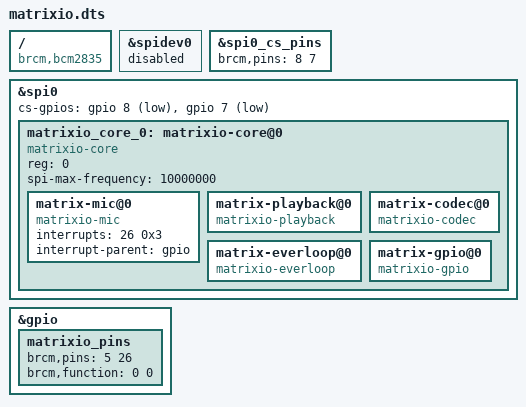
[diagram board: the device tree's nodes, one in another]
/dts-v1/;
/plugin/;

/ {
	compatible = "brcm,bcm2835";

	fragment@0 {
		target = <&spidev0>;
		__overlay__ { status = "disabled"; };
	};

	fragment@1 {
		target = <&spi0_cs_pins>;
		frag1: __overlay__ {
			brcm,pins = <8 7>;
		};
	};

	fragment@2 {
		target = <&spi0>;
		frag2: __overlay__ {
			cs-gpios = <&gpio 8 1>, <&gpio 7 1>;
			status = "okay";

			#address-cells = <1>;
			#size-cells = <0>;

			matrixio_core_0: matrixio-core@0{
				compatible = "matrixio-core";
				reg = <0>;
				spi-max-frequency = <10000000>;
				status = "okay";
			};
		};
	};

	fragment@3 {
		target = <&gpio>;
		__overlay__ {
			matrixio_pins: matrixio_pins {
				brcm,pins = <5 26>; /* pin 26 for general GPIO, pin 5 for reset */
				brcm,function = <0 0>;
			};
		};
	};

        fragment@10 {
                target = <&matrixio_core_0>;
                __overlay__ {
                        matrix-mic@0 {
                                compatible = "matrixio-mic";
                                interrupts = <26 0x3>; /* CHANGED: Use pin 26 instead of pin 6 */
                                interrupt-parent = <&gpio>;
                        };
                };
        };
        fragment@11 {
                target = <&matrixio_core_0>;
                __overlay__ {
                        matrix-playback@0 {
                                compatible = "matrixio-playback";
                        };
                };
        };
        fragment@12 {
                target = <&matrixio_core_0>;
                __overlay__ {
                        matrix-codec@0 {
                                compatible = "matrixio-codec";
                        };
                };
        };
        fragment@13 {
                target = <&matrixio_core_0>;
                __overlay__ {
                        matrix-everloop@0 {
                                compatible = "matrixio-everloop";
                        };
                };
        };
        fragment@14 {
                target = <&matrixio_core_0>;
                __overlay__ {
                        matrix-gpio@0 {
                                compatible = "matrixio-gpio";
                        };
                };
        };

	__overrides__ {
		cs0_pin  = <&frag1>,"brcm,pins:0",
			   <&frag2>,"cs-gpios:4";
		cs1_pin  = <&frag1>,"brcm,pins:4",
			   <&frag2>,"cs-gpios:16";
	};
};
